# STM32F413 register map
File version: 1.9
CPU: CM4 r0p1, little endian, MPU, FPU, 4 interrupt priority bits
Registers are 32-bit, read-write, reset 0x0 unless marked. A register's access mark holds for its fields unless they carry their own. Offsets are from the block's base; [hi:lo] are bit positions; {n}, {i} and the like mark numbered series.

## RNG — Random number generator
Base 0x50060800
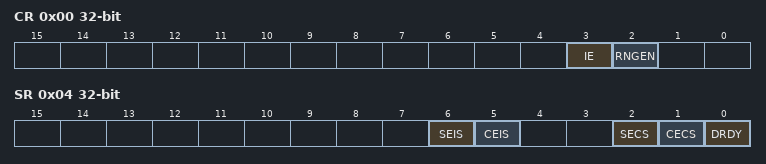
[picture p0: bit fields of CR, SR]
0x00 CR — control register
  [3] IE — Interrupt enable
  [2] RNGEN — Random number generator enable
0x04 SR access per field — status register
  [6] SEIS rw — Seed error interrupt status
  [5] CEIS rw — Clock error interrupt status
  [2] SECS ro — Seed error current status
  [1] CECS ro — Clock error current status
  [0] DRDY ro — Data ready
0x08 DR ro — data register
  [31:0] RNDATA — Random data

## SPI5 — Serial peripheral interface
Base 0x40015000
Same registers: SPI2 0x40003800, SPI3 0x40003C00, SPI1 0x40013000, SPI4 0x40013400, SPI6 0x40015400
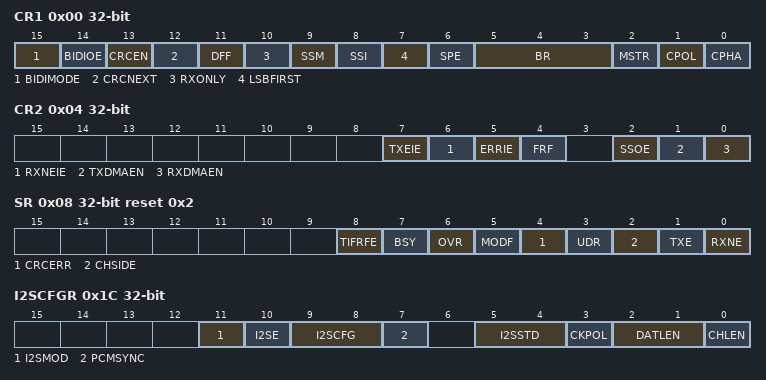
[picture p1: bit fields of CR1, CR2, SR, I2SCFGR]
0x00 CR1 — control register 1
  [15] BIDIMODE — Bidirectional data mode enable
  [14] BIDIOE — Output enable in bidirectional mode
  [13] CRCEN — Hardware CRC calculation enable
  [12] CRCNEXT — CRC transfer next
  [11] DFF — Data frame format
  [10] RXONLY — Receive only
  [9] SSM — Software slave management
  [8] SSI — Internal slave select
  [7] LSBFIRST — Frame format
  [6] SPE — SPI enable
  [5:3] BR — Baud rate control
  [2] MSTR — Master selection
  [1] CPOL — Clock polarity
  [0] CPHA — Clock phase
0x04 CR2 — control register 2
  [7] TXEIE — Tx buffer empty interrupt enable
  [6] RXNEIE — RX buffer not empty interrupt enable
  [5] ERRIE — Error interrupt enable
  [4] FRF — Frame format
  [2] SSOE — SS output enable
  [1] TXDMAEN — Tx buffer DMA enable
  [0] RXDMAEN — Rx buffer DMA enable
0x08 SR access per field reset 0x2 — status register
  [8] TIFRFE ro — TI frame format error
  [7] BSY ro — Busy flag
  [6] OVR ro — Overrun flag
  [5] MODF ro — Mode fault
  [4] CRCERR rw write-0-clears — CRC error flag
  [3] UDR ro — Underrun flag
  [2] CHSIDE ro — Channel side
  [1] TXE ro — Transmit buffer empty
  [0] RXNE ro — Receive buffer not empty
0x0C DR — data register
  [15:0] DR — Data register
0x10 CRCPR reset 0x7 — CRC polynomial register
  [15:0] CRCPOLY
0x14 RXCRCR ro — RX CRC register
  [15:0] RxCRC
0x18 TXCRCR ro — TX CRC register
  [15:0] TxCRC
0x1C I2SCFGR — I2S configuration register
  [11] I2SMOD — I2S mode selection
  [10] I2SE — I2S Enable
  [9:8] I2SCFG — I2S configuration mode
  [7] PCMSYNC — PCM frame synchronization
  [5:4] I2SSTD — I2S standard selection
  [3] CKPOL — Steady state clock polarity
  [2:1] DATLEN — Data length to be transferred
  [0] CHLEN — Channel length (number of bits per audio channel)
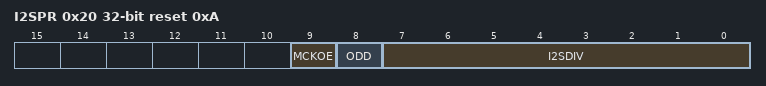
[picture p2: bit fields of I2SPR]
0x20 I2SPR reset 0xA — I2S prescaler register
  [9] MCKOE — Master clock output enable
  [8] ODD — Odd factor for the prescaler
  [7:0] I2SDIV — I2S Linear prescaler

## SYSCFG — System configuration controller
Base 0x40013800
0x00 MEMRM — memory remap register
  [1:0] MEM_MODE
0x04 PMC — peripheral mode configuration register
  [16] ADC1DC2
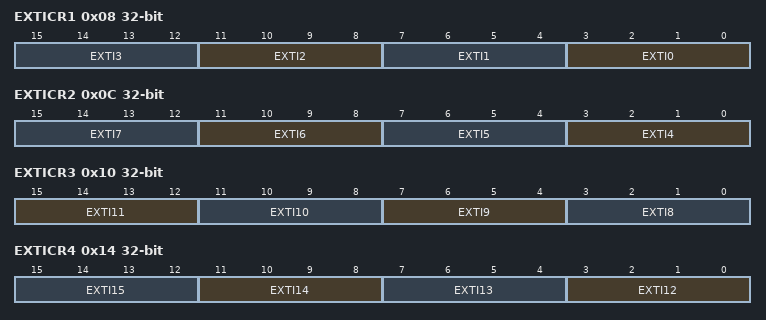
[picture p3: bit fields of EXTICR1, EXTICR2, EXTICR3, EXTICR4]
0x08 EXTICR1 — external interrupt configuration register 1
  [4n+3:4n] EXTI{n} (n=0..3) — EXTI x configuration (x = 0 to 3)
0x0C EXTICR2 — external interrupt configuration register 2
  [4n-13:4n-16] EXTI{n} (n=4..7) — EXTI x configuration (x = 4 to 7)
0x10 EXTICR3 — external interrupt configuration register 3
  [15:12] EXTI11 — EXTI x configuration (x = 8 to 11)
  [11:8] EXTI10
  [7:4] EXTI9 — EXTI x configuration (x = 8 to 11)
  [3:0] EXTI8 — EXTI x configuration (x = 8 to 11)
0x14 EXTICR4 — external interrupt configuration register 4
  [4n-45:4n-48] EXTI{n} (n=12..15) — EXTI x configuration (x = 12 to 15)
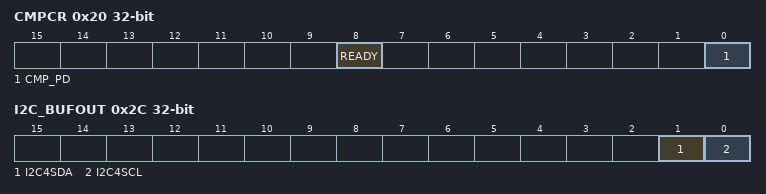
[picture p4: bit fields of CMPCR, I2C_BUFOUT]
0x20 CMPCR ro — Compensation cell control register
  [8] READY
  [0] CMP_PD — Compensation cell power-down
0x2C I2C_BUFOUT
  [1] I2C4SDA, [0] I2C4SCL

## USART3 — Universal synchronous asynchronous receiver transmitter
Base 0x40004800
Same registers: USART2 0x40004400, UART4 0x40004C00, UART5 0x40005000, UART7 0x40007800, UART8 0x40007C00, USART1 0x40011000, USART6 0x40011400, UART9 0x40011800, UART10 0x40011C00
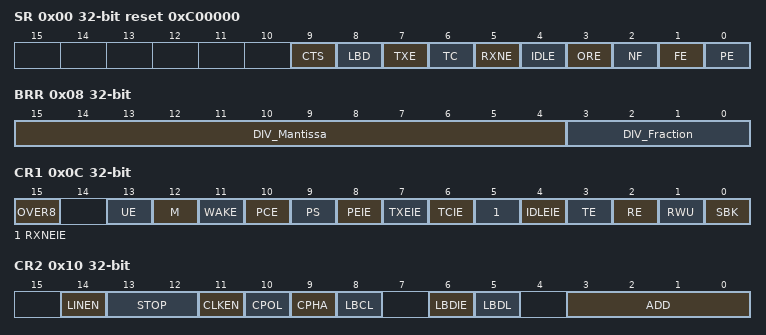
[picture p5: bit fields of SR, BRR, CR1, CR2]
0x00 SR access per field reset 0xC00000 — Status register
  [9] CTS rw write-0-clears — CTS flag
  [8] LBD rw write-0-clears — LIN break detection flag
  [7] TXE ro — Transmit data register empty
  [6] TC rw write-0-clears — Transmission complete
  [5] RXNE rw write-0-clears — Read data register not empty
  [4] IDLE ro — IDLE line detected
  [3] ORE ro — Overrun error
  [2] NF ro — Noise detected flag
  [1] FE ro — Framing error
  [0] PE ro — Parity error
0x04 DR — Data register
  [8:0] DR — Data value
0x08 BRR — Baud rate register
  [15:4] DIV_Mantissa — mantissa of USARTDIV
  [3:0] DIV_Fraction — fraction of USARTDIV
0x0C CR1 — Control register 1
  [15] OVER8 — Oversampling mode
  [13] UE — USART enable
  [12] M — Word length
  [11] WAKE — Wakeup method
  [10] PCE — Parity control enable
  [9] PS — Parity selection
  [8] PEIE — PE interrupt enable
  [7] TXEIE — TXE interrupt enable
  [6] TCIE — Transmission complete interrupt enable
  [5] RXNEIE — RXNE interrupt enable
  [4] IDLEIE — IDLE interrupt enable
  [3] TE — Transmitter enable
  [2] RE — Receiver enable
  [1] RWU — Receiver wakeup
  [0] SBK — Send break
0x10 CR2 — Control register 2
  [14] LINEN — LIN mode enable
  [13:12] STOP — STOP bits
  [11] CLKEN — Clock enable
  [10] CPOL — Clock polarity
  [9] CPHA — Clock phase
  [8] LBCL — Last bit clock pulse
  [6] LBDIE — LIN break detection interrupt enable
  [5] LBDL — lin break detection length
  [3:0] ADD — Address of the USART node
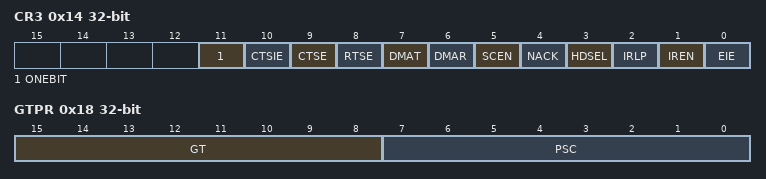
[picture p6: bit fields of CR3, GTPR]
0x14 CR3 — Control register 3
  [11] ONEBIT — One sample bit method enable
  [10] CTSIE — CTS interrupt enable
  [9] CTSE — CTS enable
  [8] RTSE — RTS enable
  [7] DMAT — DMA enable transmitter
  [6] DMAR — DMA enable receiver
  [5] SCEN — Smartcard mode enable
  [4] NACK — Smartcard NACK enable
  [3] HDSEL — Half-duplex selection
  [2] IRLP — IrDA low-power
  [1] IREN — IrDA mode enable
  [0] EIE — Error interrupt enable
0x18 GTPR — Guard time and prescaler register
  [15:8] GT — Guard time value
  [7:0] PSC — Prescaler value
